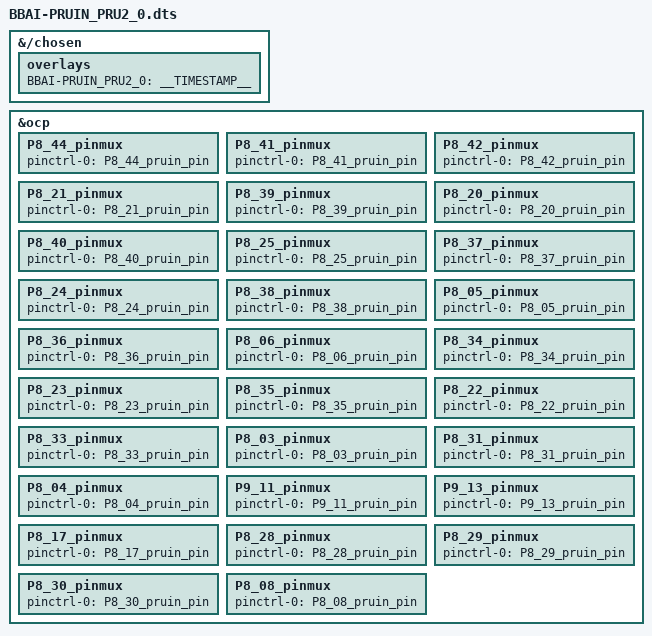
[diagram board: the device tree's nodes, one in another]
/*
 * Copyright (C) 2020 Deepak Khatri <deepaklorkhatri7@gmail.com>
 * See Cape Interface Spec page for more info on Bone Buses
 * https://elinux.org/Beagleboard:BeagleBone_cape_interface_spec
 *
 * Virtual cape for pr2_pru0_gpi* pins
 *
 * This program is free software; you can redistribute it and/or modify
 * it under the terms of the GNU General Public License version 2 as
 * published by the Free Software Foundation.
 */
/dts-v1/;
/plugin/;

/*
* Helper to show loaded overlays under: /proc/device-tree/chosen/overlays/
*/
&{/chosen} {
    overlays {
        BBAI-PRUIN_PRU2_0 = __TIMESTAMP__;
    };
};

/*
 * Update the default pinmux of the pins.
 * See these files for the phandles (&P9_* & &P8_*)
 * BeagleBoard-DeviceTrees/v4.19.x-ti-overlays/src/arm/am335x-bone-common-univ.dtsi
 * BeagleBoard-DeviceTrees/v4.19.x-ti-overlays/src/arm/am572x-bone-common-univ.dtsi
 */
&ocp {
    P8_44_pinmux { pinctrl-0 = <&P8_44_pruin_pin>; }; /* pr2_pru0_gpi0 */
	P8_41_pinmux { pinctrl-0 = <&P8_41_pruin_pin>; }; /* pr2_pru0_gpi1 */

	P8_42_pinmux { pinctrl-0 = <&P8_42_pruin_pin>; }; /* pr2_pru0_gpi2 */
	P8_21_pinmux { pinctrl-0 = <&P8_21_pruin_pin>; }; /* pr2_pru0_gpi2 */

	P8_39_pinmux { pinctrl-0 = <&P8_39_pruin_pin>; }; /* pr2_pru0_gpi3 */
	P8_20_pinmux { pinctrl-0 = <&P8_20_pruin_pin>; }; /* pr2_pru0_gpi3 */

	P8_40_pinmux { pinctrl-0 = <&P8_40_pruin_pin>; }; /* pr2_pru0_gpi4 */
	P8_25_pinmux { pinctrl-0 = <&P8_25_pruin_pin>; }; /* pr2_pru0_gpi4 */

	P8_37_pinmux { pinctrl-0 = <&P8_37_pruin_pin>; }; /* pr2_pru0_gpi5 */
	P8_24_pinmux { pinctrl-0 = <&P8_24_pruin_pin>; }; /* pr2_pru0_gpi5 */

	P8_38_pinmux { pinctrl-0 = <&P8_38_pruin_pin>; }; /* pr2_pru0_gpi6 */
	P8_05_pinmux { pinctrl-0 = <&P8_05_pruin_pin>; }; /* pr2_pru0_gpi6 */

	P8_36_pinmux { pinctrl-0 = <&P8_36_pruin_pin>; }; /* pr2_pru0_gpi7 */
	P8_06_pinmux { pinctrl-0 = <&P8_06_pruin_pin>; }; /* pr2_pru0_gpi7 */

	P8_34_pinmux { pinctrl-0 = <&P8_34_pruin_pin>; }; /* pr2_pru0_gpi8 */
	P8_23_pinmux { pinctrl-0 = <&P8_23_pruin_pin>; }; /* pr2_pru0_gpi8 */

	P8_35_pinmux { pinctrl-0 = <&P8_35_pruin_pin>; }; /* pr2_pru0_gpi9 */
	P8_22_pinmux { pinctrl-0 = <&P8_22_pruin_pin>; }; /* pr2_pru0_gpi9 */

	P8_33_pinmux { pinctrl-0 = <&P8_33_pruin_pin>; }; /* pr2_pru0_gpi10 */
	P8_03_pinmux { pinctrl-0 = <&P8_03_pruin_pin>; }; /* pr2_pru0_gpi10 */

	P8_31_pinmux { pinctrl-0 = <&P8_31_pruin_pin>; }; /* pr2_pru0_gpi11 */
	P8_04_pinmux { pinctrl-0 = <&P8_04_pruin_pin>; }; /* pr2_pru0_gpi11 */


    P9_11_pinmux { pinctrl-0 = <&P9_11_pruin_pin>; }; /* pr2_pru0_gpi */

	P9_13_pinmux { pinctrl-0 = <&P9_13_pruin_pin>; }; /* pr2_pru0_gpi */
	P8_17_pinmux { pinctrl-0 = <&P8_17_pruin_pin>; }; /* pr2_pru0_gpi */

	P8_28_pinmux { pinctrl-0 = <&P8_28_pruin_pin>; }; /* pr2_pru0_gpi */
	P8_29_pinmux { pinctrl-0 = <&P8_29_pruin_pin>; }; /* pr2_pru0_gpi */
	P8_30_pinmux { pinctrl-0 = <&P8_30_pruin_pin>; }; /* pr2_pru0_gpi */
	P8_08_pinmux { pinctrl-0 = <&P8_08_pruin_pin>; }; /* pr2_pru0_gpi */
};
